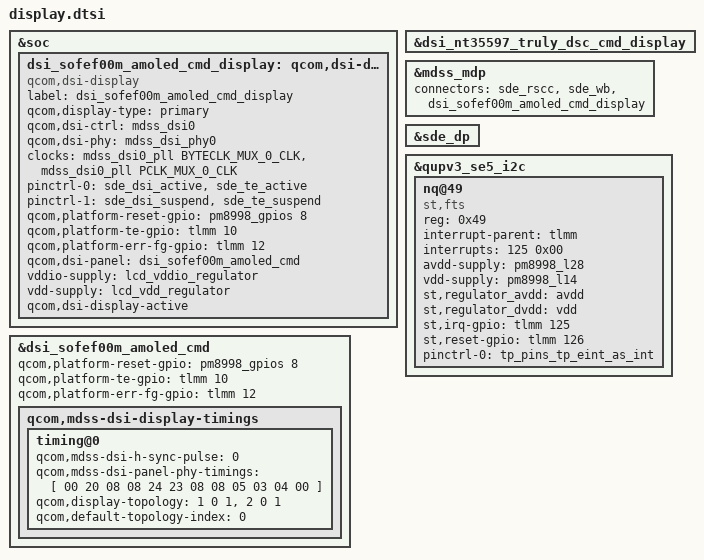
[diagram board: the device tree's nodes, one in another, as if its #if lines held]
/*
 * Copyright (c) 2024, MeizuCustoms enthusiasts
 *
 * This program is free software; you can redistribute it and/or modify
 * it under the terms of the GNU General Public License version 2 and
 * only version 2 as published by the Free Software Foundation.
 *
 * This program is distributed in the hope that it will be useful,
 * but WITHOUT ANY WARRANTY; without even the implied warranty of
 * MERCHANTABILITY or FITNESS FOR A PARTICULAR PURPOSE.  See the
 * GNU General Public License for more details.
 */

#ifdef MZ_M1892
#include "dsi-panel-sofef00m-amoled-fhd-cmd-m1892.dtsi"
#else
#include "dsi-panel-sofef00m-amoled-fhd-cmd.dtsi"
#endif

&soc {
	/delete-node/ qcom,dsi-display@17;

    dsi_sofef00m_amoled_cmd_display: qcom,dsi-display@17 {
		compatible = "qcom,dsi-display";
		label = "dsi_sofef00m_amoled_cmd_display";
		qcom,display-type = "primary";

		qcom,dsi-ctrl = <&mdss_dsi0>;
		qcom,dsi-phy = <&mdss_dsi_phy0>;
		clocks = <&mdss_dsi0_pll BYTECLK_MUX_0_CLK>,
			<&mdss_dsi0_pll PCLK_MUX_0_CLK>;
		clock-names = "mux_byte_clk", "mux_pixel_clk";

		pinctrl-names = "panel_active", "panel_suspend";
		pinctrl-0 = <&sde_dsi_active &sde_te_active>;
		pinctrl-1 = <&sde_dsi_suspend &sde_te_suspend>;
		qcom,platform-reset-gpio = <&pm8998_gpios 8 0>;
    	qcom,platform-te-gpio = <&tlmm 10 0>;
    	qcom,platform-err-fg-gpio = <&tlmm 12 0>;

		qcom,dsi-panel = <&dsi_sofef00m_amoled_cmd>;
		vddio-supply = <&lcd_vddio_regulator>;
		vdd-supply = <&lcd_vdd_regulator>;

		qcom,dsi-display-active;
	};
};

&dsi_sofef00m_amoled_cmd {
	qcom,platform-reset-gpio = <&pm8998_gpios 8 0>;
	qcom,platform-te-gpio = <&tlmm 10 0>;
	qcom,platform-err-fg-gpio = <&tlmm 12 0>;

	qcom,mdss-dsi-display-timings {
		timing@0 {
			qcom,mdss-dsi-h-sync-pulse = <0>;
			qcom,mdss-dsi-panel-phy-timings = [
				00 20 08 08 24 23 08 08 05 03 04 00
			];
			qcom,display-topology = <1 0 1>, <2 0 1>;
			qcom,default-topology-index = <0>;
		};
	};
};

&dsi_nt35597_truly_dsc_cmd_display {
    /delete-property/ qcom,dsi-display-active;
};

&mdss_mdp {
	connectors = <&sde_rscc &sde_wb &dsi_sofef00m_amoled_cmd_display>;
};

&sde_dp {
    /delete-property/ qcom,aux-sel-gpio;
};

/* m1882: ST FTS touchscreen; m1892 uses Synaptics DSX (see m1892-overlay.dtsi) */
#ifndef MZ_M1892
&qupv3_se5_i2c {
	status = "ok";

	nq@49 {
		compatible = "st,fts";
		reg = <0x49>;
		interrupt-parent = <&tlmm>;
		interrupts = <125 0x00>;
		avdd-supply = <&pm8998_l28>;
		vdd-supply = <&pm8998_l14>;
		st,regulator_avdd = "avdd";
		st,regulator_dvdd = "vdd";
		st,irq-gpio = <&tlmm 125 0x0>;
		st,reset-gpio = <&tlmm 126 0x0>;
		pinctrl-names = "tp_int";
		pinctrl-0 = <&tp_pins_tp_eint_as_int>;
	};
};
#endif
